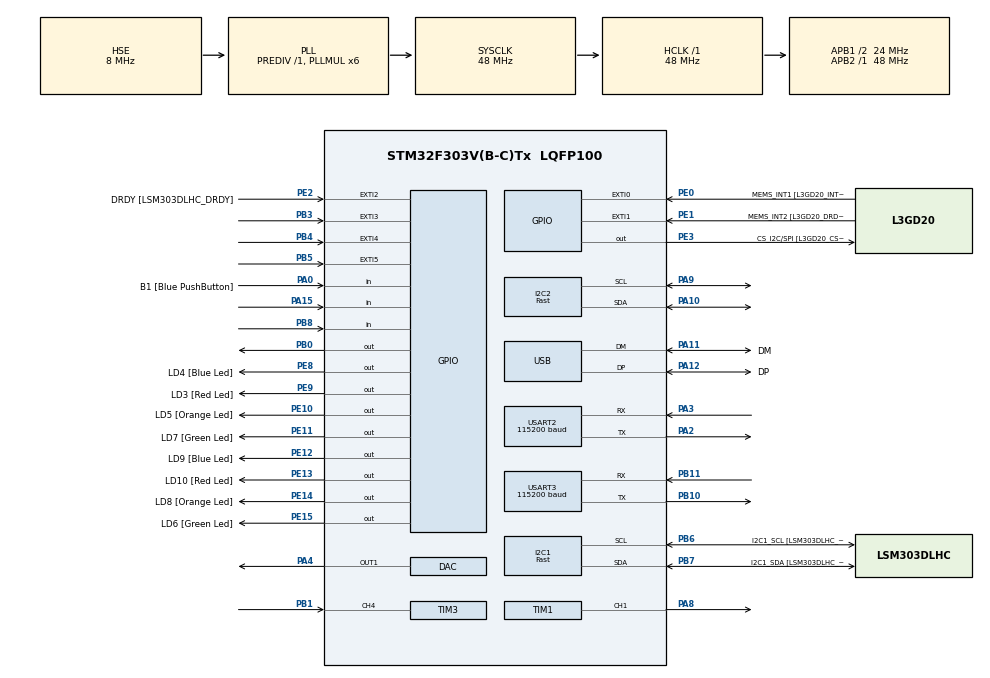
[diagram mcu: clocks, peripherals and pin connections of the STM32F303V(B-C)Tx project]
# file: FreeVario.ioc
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ADC1.Channel-4\#ChannelRegularConversion=ADC_CHANNEL_VBAT
ADC1.ClockPrescaler=ADC_CLOCK_ASYNC_DIV1
ADC1.ContinuousConvMode=ENABLE
ADC1.DMAContinuousRequests=DISABLE
ADC1.DataAlign=ADC_DATAALIGN_RIGHT
ADC1.DiscontinuousConvMode=DISABLE
ADC1.EOCSelection=ADC_EOC_SINGLE_CONV
ADC1.EnableAnalogWatchDog1=false
ADC1.EnableAnalogWatchDog2=false
ADC1.EnableAnalogWatchDog3=false
ADC1.EnableInjectedConversion=ENABLE
ADC1.EnableRegularConversion=ENABLE
ADC1.ExternalTrigConv=ADC_SOFTWARE_START
ADC1.ExternalTrigConvEdge=ADC_EXTERNALTRIGCONVEDGE_NONE
ADC1.InjNumberOfConversion=0
ADC1.LowPowerAutoWait=DISABLE
ADC1.NbrOfConversion=1
ADC1.NbrOfConversionFlag=1
ADC1.Offset-4\#ChannelRegularConversion=0
ADC1.OffsetNumber-4\#ChannelRegularConversion=ADC_OFFSET_NONE
ADC1.Overrun=ADC_OVR_DATA_OVERWRITTEN
ADC1.Rank-4\#ChannelRegularConversion=1
ADC1.Resolution=ADC_RESOLUTION_12B
ADC1.SamplingTime-4\#ChannelRegularConversion=ADC_SAMPLETIME_1CYCLE_5
ADC1.ScanConvMode=ADC_SCAN_DISABLE
ADC1.master=1
DAC.DAC_Trigger=DAC_TRIGGER_T6_TRGO
Dma.DAC_CH1.1.Direction=DMA_MEMORY_TO_PERIPH
Dma.DAC_CH1.1.Instance=DMA1_Channel3
Dma.DAC_CH1.1.MemDataAlignment=DMA_MDATAALIGN_HALFWORD
Dma.DAC_CH1.1.MemInc=DMA_MINC_ENABLE
Dma.DAC_CH1.1.Mode=DMA_CIRCULAR
Dma.DAC_CH1.1.PeriphDataAlignment=DMA_PDATAALIGN_HALFWORD
Dma.DAC_CH1.1.PeriphInc=DMA_PINC_DISABLE
Dma.DAC_CH1.1.Priority=DMA_PRIORITY_LOW
Dma.Request0=USART2_RX
Dma.Request1=DAC_CH1
Dma.USART2_RX.0.Direction=DMA_PERIPH_TO_MEMORY
Dma.USART2_RX.0.Instance=DMA1_Channel6
Dma.USART2_RX.0.MemDataAlignment=DMA_MDATAALIGN_BYTE
Dma.USART2_RX.0.MemInc=DMA_MINC_ENABLE
Dma.USART2_RX.0.Mode=DMA_CIRCULAR
Dma.USART2_RX.0.PeriphDataAlignment=DMA_PDATAALIGN_BYTE
Dma.USART2_RX.0.PeriphInc=DMA_PINC_DISABLE
Dma.USART2_RX.0.Priority=DMA_PRIORITY_LOW
I2C1.Analog_Filter=I2C_ANALOGFILTER_ENABLE
I2C1.I2C_Coeff_DF=0
I2C1.I2C_Speed_Mode=I2C_Fast
I2C1.Timing=0x2010091A
I2C2.I2C_Coeff_DF=2
I2C2.I2C_Speed_Mode=I2C_Fast
I2C2.Timing=0x00401653
IWDG.Prescaler=IWDG_PRESCALER_32
Mcu.Family=STM32F3
Mcu.Name=STM32F303V(B-C)Tx
Mcu.Package=LQFP100
NVIC.DMA1_Channel3_IRQn=true\:0\:0\:false\:false\:true\:false
NVIC.DMA1_Channel6_IRQn=true\:0\:0\:false\:false\:true\:false
NVIC.EXTI3_IRQn=true\:0\:0\:false\:false\:true\:true
NVIC.EXTI4_IRQn=true\:0\:0\:false\:false\:true\:true
NVIC.EXTI9_5_IRQn=true\:0\:0\:false\:false\:true\:true
NVIC.PriorityGroup=NVIC_PRIORITYGROUP_0
NVIC.USB_LP_CAN_RX0_IRQn=true\:0\:0\:false\:false\:true\:false
PA0.GPIO_Label=B1 [Blue PushButton]
PA0.GPIO_Mode=GPIO_MODE_INPUT
PA0.GPIO_PuPd=GPIO_NOPULL
PA0.Signal=GPIO_Input
PA10.Mode=I2C
PA10.Signal=I2C2_SDA
PA11.GPIO_Label=DM
PA11.Mode=Device
PA11.Signal=USB_DM
PA12.GPIO_Label=DP
PA12.Mode=Device
PA12.Signal=USB_DP
PA13.GPIO_Label=SWDIO
PA13.Mode=Serial_Wire
PA13.Signal=SYS_JTMS-SWDIO
PA14.GPIO_Label=SWCLK
PA14.Mode=Serial_Wire
PA14.Signal=SYS_JTCK-SWCLK
PA15.Signal=GPIO_Input
PA2.Mode=Asynchronous
PA2.Signal=USART2_TX
PA3.Mode=Asynchronous
PA3.Signal=USART2_RX
PA4.Signal=COMP_DAC1_group
PA5.GPIO_Label=SPI1_SCK [L3GD20_SCL/SPC]
PA5.GPIO_Mode=GPIO_MODE_AF_PP
PA5.GPIO_PuPd=GPIO_NOPULL
PA5.GPIO_Speed=GPIO_SPEED_FREQ_LOW
PA5.Signal=SPI1_SCK
PA6.GPIO_Label=SPI1_MISO [L3GD20_SA0/SDO]
PA6.GPIO_Mode=GPIO_MODE_AF_PP
PA6.GPIO_PuPd=GPIO_NOPULL
PA6.GPIO_Speed=GPIO_SPEED_FREQ_LOW
PA6.Signal=SPI1_MISO
PA7.GPIO_Label=SPI1_MISO [L3GD20_SDA/SDI/SDO]
PA7.GPIO_Mode=GPIO_MODE_AF_PP
PA7.GPIO_PuPd=GPIO_NOPULL
PA7.GPIO_Speed=GPIO_SPEED_FREQ_LOW
PA7.Signal=SPI1_MOSI
PA8.Signal=S_TIM1_CH1
PA9.Mode=I2C
PA9.Signal=I2C2_SCL
PB0.Signal=GPIO_Output
PB1.Signal=S_TIM3_CH4
PB10.Mode=Asynchronous
PB10.Signal=USART3_TX
PB11.Mode=Asynchronous
PB11.Signal=USART3_RX
PB3.Signal=GPXTI3
PB4.Signal=GPXTI4
PB5.Signal=GPXTI5
PB6.GPIO_FM6=__NULL
PB6.GPIO_Label=I2C1_SCL [LSM303DLHC_SCL]
PB6.GPIO_Mode=GPIO_MODE_AF_OD
PB6.GPIO_PuPd=GPIO_NOPULL
PB6.GPIO_Speed=GPIO_SPEED_FREQ_LOW
PB6.Mode=I2C
PB6.Signal=I2C1_SCL
PB7.GPIO_FM7=__NULL
PB7.GPIO_Label=I2C1_SDA [LSM303DLHC_SDA]
PB7.GPIO_Mode=GPIO_MODE_AF_OD
PB7.GPIO_PuPd=GPIO_NOPULL
PB7.GPIO_Speed=GPIO_SPEED_FREQ_LOW
PB7.Mode=I2C
PB7.Signal=I2C1_SDA
PB8.Signal=GPIO_Input
PC14-OSC32_IN.GPIO_Label=OSC32_IN
PC14-OSC32_IN.Signal=RCC_OSC32_IN
PC15-OSC32_OUT.GPIO_Label=OSC32_OUT
PC15-OSC32_OUT.Signal=RCC_OSC32_OUT
PE0.GPIO_Label=MEMS_INT1 [L3GD20_INT1]
PE0.GPIO_ModeDefaultEXTI=GPIO_MODE_EVT_RISING
PE0.GPIO_PuPd=GPIO_NOPULL
PE0.Signal=GPXTI0
PE1.GPIO_Label=MEMS_INT2 [L3GD20_DRDY/INT2]
PE1.GPIO_ModeDefaultEXTI=GPIO_MODE_EVT_RISING
PE1.GPIO_PuPd=GPIO_NOPULL
PE1.Signal=GPXTI1
PE10.GPIO_Label=LD5 [Orange Led]
PE10.GPIO_ModeDefaultOutputPP=GPIO_MODE_OUTPUT_PP
PE10.GPIO_PuPd=GPIO_NOPULL
PE10.GPIO_Speed=GPIO_SPEED_FREQ_LOW
PE10.Signal=GPIO_Output
PE11.GPIO_Label=LD7 [Green Led]
PE11.GPIO_ModeDefaultOutputPP=GPIO_MODE_OUTPUT_PP
PE11.GPIO_PuPd=GPIO_NOPULL
PE11.GPIO_Speed=GPIO_SPEED_FREQ_LOW
PE11.Signal=GPIO_Output
PE12.GPIO_Label=LD9 [Blue Led]
PE12.GPIO_ModeDefaultOutputPP=GPIO_MODE_OUTPUT_PP
PE12.GPIO_PuPd=GPIO_NOPULL
PE12.GPIO_Speed=GPIO_SPEED_FREQ_LOW
PE12.Signal=GPIO_Output
PE13.GPIO_Label=LD10 [Red Led]
PE13.GPIO_ModeDefaultOutputPP=GPIO_MODE_OUTPUT_PP
PE13.GPIO_PuPd=GPIO_NOPULL
PE13.GPIO_Speed=GPIO_SPEED_FREQ_LOW
PE13.Signal=GPIO_Output
PE14.GPIO_Label=LD8 [Orange Led]
PE14.GPIO_ModeDefaultOutputPP=GPIO_MODE_OUTPUT_PP
PE14.GPIO_PuPd=GPIO_NOPULL
PE14.GPIO_Speed=GPIO_SPEED_FREQ_LOW
PE14.Signal=GPIO_Output
PE15.GPIO_Label=LD6 [Green Led]
PE15.GPIO_ModeDefaultOutputPP=GPIO_MODE_OUTPUT_PP
PE15.GPIO_PuPd=GPIO_NOPULL
PE15.GPIO_Speed=GPIO_SPEED_FREQ_LOW
PE15.Signal=GPIO_Output
PE2.GPIO_Label=DRDY [LSM303DLHC_DRDY]
PE2.GPIO_ModeDefaultEXTI=GPIO_MODE_EVT_RISING
PE2.GPIO_PuPd=GPIO_NOPULL
PE2.Signal=GPXTI2
PE3.GPIO_Label=CS_I2C/SPI [L3GD20_CS_I2C/SPI]
PE3.GPIO_ModeDefaultOutputPP=GPIO_MODE_OUTPUT_PP
PE3.GPIO_PuPd=GPIO_NOPULL
PE3.GPIO_Speed=GPIO_SPEED_FREQ_LOW
PE3.Signal=GPIO_Output
PE8.GPIO_Label=LD4 [Blue Led]
PE8.GPIO_ModeDefaultOutputPP=GPIO_MODE_OUTPUT_PP
PE8.GPIO_PuPd=GPIO_NOPULL
PE8.GPIO_Speed=GPIO_SPEED_FREQ_LOW
PE8.Signal=GPIO_Output
PE9.GPIO_Label=LD3 [Red Led]
PE9.GPIO_ModeDefaultOutputPP=GPIO_MODE_OUTPUT_PP
PE9.GPIO_PuPd=GPIO_NOPULL
PE9.GPIO_Speed=GPIO_SPEED_FREQ_LOW
PE9.Signal=GPIO_Output
PF0-OSC_IN.GPIO_Label=OSC_IN
PF0-OSC_IN.Mode=HSE-External-Clock-Source
PF0-OSC_IN.Signal=RCC_OSC_IN
PF1-OSC_OUT.GPIO_Label=OSC_OUT
PF1-OSC_OUT.Signal=RCC_OSC_OUT
ProjectManager.HeapSize=0x200
ProjectManager.StackSize=0x400
ProjectManager.TargetToolchain=TrueSTUDIO
RCC.AHBFreq_Value=48000000
RCC.APB1CLKDivider=RCC_HCLK_DIV2
RCC.APB1Freq_Value=24000000
RCC.APB1TimFreq_Value=48000000
RCC.APB2Freq_Value=48000000
RCC.APB2TimFreq_Value=48000000
RCC.CortexFreq_Value=48000000
RCC.HCLKFreq_Value=48000000
RCC.HSE_VALUE=8000000
RCC.HSI_VALUE=8000000
RCC.I2c1ClockSelection=RCC_I2C1CLKSOURCE_SYSCLK
RCC.I2c2ClockSelection=RCC_I2C2CLKSOURCE_SYSCLK
RCC.LSE_VALUE=32768
RCC.PLLMUL=RCC_PLL_MUL6
RCC.SYSCLKFreq_VALUE=48000000
RCC.SYSCLKSourceVirtual=RCC_SYSCLKSOURCE_PLLCLK
RCC.USBFreq_Value=48000000
SH.COMP_DAC1_group.0=DAC_OUT1,DAC_OUT1
SH.S_TIM1_CH1.0=TIM1_CH1,PWM Generation1 CH1
SH.S_TIM3_CH4.0=TIM3_CH4,Input_Capture4_from_TI4
TIM1.Channel-PWM\ Generation1\ CH1=TIM_CHANNEL_1
TIM1.OCPolarity_1=TIM_OCPOLARITY_LOW
TIM3.Channel-Input_Capture4_from_TI4=TIM_CHANNEL_4
TIM6.TIM_MasterOutputTrigger=TIM_TRGO_UPDATE
USART2.BaudRate=115200
USART2.DMADisableonRxErrorParam=ADVFEATURE_DMA_DISABLEONRXERROR
USART2.OverSampling=UART_OVERSAMPLING_8
USART2.OverrunDisableParam=ADVFEATURE_OVERRUN_DISABLE
USART2.VirtualMode-Asynchronous=VM_ASYNC
USART3.BaudRate=115200
USART3.VirtualMode-Asynchronous=VM_ASYNC
USB_DEVICE.CLASS_NAME_FS=CDC
USB_DEVICE.VirtualMode=Cdc
USB_DEVICE.VirtualModeFS=Cdc_FS
VP_ADC1_Vbat_Input.Mode=IN-Vbat
VP_IWDG_VS_IWDG.Mode=IWDG_Activate
VP_TIM1_VS_ClockSourceINT.Mode=Internal
VP_TIM6_VS_ClockSourceINT.Mode=Enable_Timer
VP_USB_DEVICE_VS_USB_DEVICE_CDC_FS.Mode=CDC_FS
board=STM32F3DISCOVERY

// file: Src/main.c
/**
  ******************************************************************************
  * File Name          : main.c
  * Description        : Main program body
  ******************************************************************************
  * This notice applies to any and all portions of this file
  * that are not between comment pairs USER CODE BEGIN and
  * USER CODE END. Other portions of this file, whether
  * inserted by the user or by software development tools
  * are owned by their respective copyright owners.
  *
  * Copyright (c) 2018 STMicroelectronics International N.V.
  * All rights reserved.
  *
  * Redistribution and use in source and binary forms, with or without
  * modification, are permitted, provided that the following conditions are met:
  *
  * 1. Redistribution of source code must retain the above copyright notice,
  *    this list of conditions and the following disclaimer.
  * 2. Redistributions in binary form must reproduce the above copyright notice,
  *    this list of conditions and the following disclaimer in the documentation
  *    and/or other materials provided with the distribution.
  * 3. Neither the name of STMicroelectronics nor the names of other
  *    contributors to this software may be used to endorse or promote products
  *    derived from this software without specific written permission.
  * 4. This software, including modifications and/or derivative works of this
  *    software, must execute solely and exclusively on microcontroller or
  *    microprocessor devices manufactured by or for STMicroelectronics.
  * 5. Redistribution and use of this software other than as permitted under
  *    this license is void and will automatically terminate your rights under
  *    this license.
  *
  * THIS SOFTWARE IS PROVIDED BY STMICROELECTRONICS AND CONTRIBUTORS "AS IS"
  * AND ANY EXPRESS, IMPLIED OR STATUTORY WARRANTIES, INCLUDING, BUT NOT
  * LIMITED TO, THE IMPLIED WARRANTIES OF MERCHANTABILITY, FITNESS FOR A
  * PARTICULAR PURPOSE AND NON-INFRINGEMENT OF THIRD PARTY INTELLECTUAL PROPERTY
  * RIGHTS ARE DISCLAIMED TO THE FULLEST EXTENT PERMITTED BY LAW. IN NO EVENT
  * SHALL STMICROELECTRONICS OR CONTRIBUTORS BE LIABLE FOR ANY DIRECT, INDIRECT,
  * INCIDENTAL, SPECIAL, EXEMPLARY, OR CONSEQUENTIAL DAMAGES (INCLUDING, BUT NOT
  * LIMITED TO, PROCUREMENT OF SUBSTITUTE GOODS OR SERVICES; LOSS OF USE, DATA,
  * OR PROFITS; OR BUSINESS INTERRUPTION) HOWEVER CAUSED AND ON ANY THEORY OF
  * LIABILITY, WHETHER IN CONTRACT, STRICT LIABILITY, OR TORT (INCLUDING
  * NEGLIGENCE OR OTHERWISE) ARISING IN ANY WAY OUT OF THE USE OF THIS SOFTWARE,
  * EVEN IF ADVISED OF THE POSSIBILITY OF SUCH DAMAGE.
  *
  ******************************************************************************
  */

#include "main.h"
#include "stm32f3xx_hal.h"
#include "usb_device.h"

/* USER CODE BEGIN Includes */
#include "freevario.h"
/* USER CODE END Includes */

ADC_HandleTypeDef hadc1;

DAC_HandleTypeDef hdac;
DMA_HandleTypeDef hdma_dac_ch1;

I2C_HandleTypeDef hi2c1;
I2C_HandleTypeDef hi2c2;

IWDG_HandleTypeDef hiwdg;

TIM_HandleTypeDef htim1;
TIM_HandleTypeDef htim3;
TIM_HandleTypeDef htim6;

UART_HandleTypeDef huart2;
UART_HandleTypeDef huart3;
DMA_HandleTypeDef hdma_usart2_rx;

/* USER CODE BEGIN PV */
/* Private variables ---------------------------------------------------------*/

/* USER CODE END PV */

void SystemClock_Config(void);
static void MX_GPIO_Init(void);
static void MX_DMA_Init(void);
static void MX_I2C1_Init(void);
static void MX_I2C2_Init(void);
static void MX_USART2_UART_Init(void);
static void MX_TIM1_Init(void);
static void MX_TIM3_Init(void);
static void MX_USART3_UART_Init(void);
static void MX_DAC_Init(void);
static void MX_TIM6_Init(void);
static void MX_IWDG_Init(void);
static void MX_ADC1_Init(void);

void HAL_TIM_MspPostInit(TIM_HandleTypeDef *htim);

/* USER CODE BEGIN PFP */
/* Private function prototypes -----------------------------------------------*/

/* USER CODE END PFP */

int main(void)
{

  /* MCU Configuration----------------------------------------------------------*/

  /* Reset of all peripherals, Initializes the Flash interface and the Systick. */
  HAL_Init();

  /* Configure the system clock */
  SystemClock_Config();

  /* Initialize all configured peripherals */
  MX_GPIO_Init();
  MX_DMA_Init();
  MX_I2C1_Init();
  MX_I2C2_Init();
  MX_USB_DEVICE_Init();
  MX_USART2_UART_Init();
  MX_TIM1_Init();
  MX_TIM3_Init();
  MX_USART3_UART_Init();
  MX_DAC_Init();
  MX_TIM6_Init();
  MX_IWDG_Init();
  MX_ADC1_Init();

  /* USER CODE BEGIN 2 */

  FV_Run();
  /* USER CODE END 2 */

  /* Infinite loop */
  while (1)
  {

  }

}

/** System Clock Configuration
*/
void SystemClock_Config(void)
{

  RCC_OscInitTypeDef RCC_OscInitStruct;
  RCC_ClkInitTypeDef RCC_ClkInitStruct;
  RCC_PeriphCLKInitTypeDef PeriphClkInit;

    /**Initializes the CPU, AHB and APB busses clocks
    */
  RCC_OscInitStruct.OscillatorType = RCC_OSCILLATORTYPE_LSI|RCC_OSCILLATORTYPE_HSE;
  RCC_OscInitStruct.HSEState = RCC_HSE_BYPASS;
  RCC_OscInitStruct.HSEPredivValue = RCC_HSE_PREDIV_DIV1;
  RCC_OscInitStruct.HSIState = RCC_HSI_ON;
  RCC_OscInitStruct.LSIState = RCC_LSI_ON;
  RCC_OscInitStruct.PLL.PLLState = RCC_PLL_ON;
  RCC_OscInitStruct.PLL.PLLSource = RCC_PLLSOURCE_HSE;
  RCC_OscInitStruct.PLL.PLLMUL = RCC_PLL_MUL6;
  if (HAL_RCC_OscConfig(&RCC_OscInitStruct) != HAL_OK)
  {
    _Error_Handler(__FILE__, __LINE__);
  }

    /**Initializes the CPU, AHB and APB busses clocks
    */
  RCC_ClkInitStruct.ClockType = RCC_CLOCKTYPE_HCLK|RCC_CLOCKTYPE_SYSCLK
                              |RCC_CLOCKTYPE_PCLK1|RCC_CLOCKTYPE_PCLK2;
  RCC_ClkInitStruct.SYSCLKSource = RCC_SYSCLKSOURCE_PLLCLK;
  RCC_ClkInitStruct.AHBCLKDivider = RCC_SYSCLK_DIV1;
  RCC_ClkInitStruct.APB1CLKDivider = RCC_HCLK_DIV2;
  RCC_ClkInitStruct.APB2CLKDivider = RCC_HCLK_DIV1;

  if (HAL_RCC_ClockConfig(&RCC_ClkInitStruct, FLASH_LATENCY_1) != HAL_OK)
  {
    _Error_Handler(__FILE__, __LINE__);
  }

  PeriphClkInit.PeriphClockSelection = RCC_PERIPHCLK_USB|RCC_PERIPHCLK_USART2
                              |RCC_PERIPHCLK_USART3|RCC_PERIPHCLK_I2C1
                              |RCC_PERIPHCLK_I2C2|RCC_PERIPHCLK_TIM1
                              |RCC_PERIPHCLK_ADC12;
  PeriphClkInit.Usart2ClockSelection = RCC_USART2CLKSOURCE_PCLK1;
  PeriphClkInit.Usart3ClockSelection = RCC_USART3CLKSOURCE_PCLK1;
  PeriphClkInit.Adc12ClockSelection = RCC_ADC12PLLCLK_DIV1;
  PeriphClkInit.I2c1ClockSelection = RCC_I2C1CLKSOURCE_SYSCLK;
  PeriphClkInit.I2c2ClockSelection = RCC_I2C2CLKSOURCE_SYSCLK;
  PeriphClkInit.USBClockSelection = RCC_USBCLKSOURCE_PLL;
  PeriphClkInit.Tim1ClockSelection = RCC_TIM1CLK_HCLK;
  if (HAL_RCCEx_PeriphCLKConfig(&PeriphClkInit) != HAL_OK)
  {
    _Error_Handler(__FILE__, __LINE__);
  }

    /**Configure the Systick interrupt time
    */
  HAL_SYSTICK_Config(HAL_RCC_GetHCLKFreq()/1000);

    /**Configure the Systick
    */
  HAL_SYSTICK_CLKSourceConfig(SYSTICK_CLKSOURCE_HCLK);

  /* SysTick_IRQn interrupt configuration */
  HAL_NVIC_SetPriority(SysTick_IRQn, 0, 0);
}

/* ADC1 init function */
static void MX_ADC1_Init(void)
{

  ADC_MultiModeTypeDef multimode;
  ADC_ChannelConfTypeDef sConfig;

    /**Common config
    */
  hadc1.Instance = ADC1;
  hadc1.Init.ClockPrescaler = ADC_CLOCK_ASYNC_DIV1;
  hadc1.Init.Resolution = ADC_RESOLUTION_12B;
  hadc1.Init.ScanConvMode = ADC_SCAN_DISABLE;
  hadc1.Init.ContinuousConvMode = ENABLE;
  hadc1.Init.DiscontinuousConvMode = DISABLE;
  hadc1.Init.ExternalTrigConvEdge = ADC_EXTERNALTRIGCONVEDGE_NONE;
  hadc1.Init.ExternalTrigConv = ADC_SOFTWARE_START;
  hadc1.Init.DataAlign = ADC_DATAALIGN_RIGHT;
  hadc1.Init.NbrOfConversion = 1;
  hadc1.Init.DMAContinuousRequests = DISABLE;
  hadc1.Init.EOCSelection = ADC_EOC_SINGLE_CONV;
  hadc1.Init.LowPowerAutoWait = DISABLE;
  hadc1.Init.Overrun = ADC_OVR_DATA_OVERWRITTEN;
  if (HAL_ADC_Init(&hadc1) != HAL_OK)
  {
    _Error_Handler(__FILE__, __LINE__);
  }

    /**Configure the ADC multi-mode
    */
  multimode.Mode = ADC_MODE_INDEPENDENT;
  if (HAL_ADCEx_MultiModeConfigChannel(&hadc1, &multimode) != HAL_OK)
  {
    _Error_Handler(__FILE__, __LINE__);
  }

    /**Configure Regular Channel
    */
  sConfig.Channel = ADC_CHANNEL_VBAT;
  sConfig.Rank = 1;
  sConfig.SingleDiff = ADC_SINGLE_ENDED;
  sConfig.SamplingTime = ADC_SAMPLETIME_1CYCLE_5;
  sConfig.OffsetNumber = ADC_OFFSET_NONE;
  sConfig.Offset = 0;
  if (HAL_ADC_ConfigChannel(&hadc1, &sConfig) != HAL_OK)
  {
    _Error_Handler(__FILE__, __LINE__);
  }

}

/* DAC init function */
static void MX_DAC_Init(void)
{

  DAC_ChannelConfTypeDef sConfig;

    /**DAC Initialization
    */
  hdac.Instance = DAC;
  if (HAL_DAC_Init(&hdac) != HAL_OK)
  {
    _Error_Handler(__FILE__, __LINE__);
  }

    /**DAC channel OUT1 config
    */
  sConfig.DAC_Trigger = DAC_TRIGGER_T6_TRGO;
  sConfig.DAC_OutputBuffer = DAC_OUTPUTBUFFER_ENABLE;
  if (HAL_DAC_ConfigChannel(&hdac, &sConfig, DAC_CHANNEL_1) != HAL_OK)
  {
    _Error_Handler(__FILE__, __LINE__);
  }

}

/* I2C1 init function */
static void MX_I2C1_Init(void)
{

  hi2c1.Instance = I2C1;
  hi2c1.Init.Timing = 0x2010091A;
  hi2c1.Init.OwnAddress1 = 0;
  hi2c1.Init.AddressingMode = I2C_ADDRESSINGMODE_7BIT;
  hi2c1.Init.DualAddressMode = I2C_DUALADDRESS_DISABLE;
  hi2c1.Init.OwnAddress2 = 0;
  hi2c1.Init.OwnAddress2Masks = I2C_OA2_NOMASK;
  hi2c1.Init.GeneralCallMode = I2C_GENERALCALL_DISABLE;
  hi2c1.Init.NoStretchMode = I2C_NOSTRETCH_DISABLE;
  if (HAL_I2C_Init(&hi2c1) != HAL_OK)
  {
    _Error_Handler(__FILE__, __LINE__);
  }

    /**Configure Analogue filter
    */
  if (HAL_I2CEx_ConfigAnalogFilter(&hi2c1, I2C_ANALOGFILTER_ENABLE) != HAL_OK)
  {
    _Error_Handler(__FILE__, __LINE__);
  }

    /**Configure Digital filter
    */
  if (HAL_I2CEx_ConfigDigitalFilter(&hi2c1, 0) != HAL_OK)
  {
    _Error_Handler(__FILE__, __LINE__);
  }

}

/* I2C2 init function */
static void MX_I2C2_Init(void)
{

  hi2c2.Instance = I2C2;
  hi2c2.Init.Timing = 0x00401653;
  hi2c2.Init.OwnAddress1 = 0;
  hi2c2.Init.AddressingMode = I2C_ADDRESSINGMODE_7BIT;
  hi2c2.Init.DualAddressMode = I2C_DUALADDRESS_DISABLE;
  hi2c2.Init.OwnAddress2 = 0;
  hi2c2.Init.OwnAddress2Masks = I2C_OA2_NOMASK;
  hi2c2.Init.GeneralCallMode = I2C_GENERALCALL_DISABLE;
  hi2c2.Init.NoStretchMode = I2C_NOSTRETCH_DISABLE;
  if (HAL_I2C_Init(&hi2c2) != HAL_OK)
  {
    _Error_Handler(__FILE__, __LINE__);
  }

    /**Configure Analogue filter
    */
  if (HAL_I2CEx_ConfigAnalogFilter(&hi2c2, I2C_ANALOGFILTER_ENABLE) != HAL_OK)
  {
    _Error_Handler(__FILE__, __LINE__);
  }

    /**Configure Digital filter
    */
  if (HAL_I2CEx_ConfigDigitalFilter(&hi2c2, 2) != HAL_OK)
  {
    _Error_Handler(__FILE__, __LINE__);
  }

}

/* IWDG init function */
static void MX_IWDG_Init(void)
{

  hiwdg.Instance = IWDG;
  hiwdg.Init.Prescaler = IWDG_PRESCALER_32;
  hiwdg.Init.Window = 4095;
  hiwdg.Init.Reload = 4095;
  if (HAL_IWDG_Init(&hiwdg) != HAL_OK)
  {
    _Error_Handler(__FILE__, __LINE__);
  }

}

/* TIM1 init function */
static void MX_TIM1_Init(void)
{

  TIM_ClockConfigTypeDef sClockSourceConfig;
  TIM_MasterConfigTypeDef sMasterConfig;
  TIM_OC_InitTypeDef sConfigOC;
  TIM_BreakDeadTimeConfigTypeDef sBreakDeadTimeConfig;

  htim1.Instance = TIM1;
  htim1.Init.Prescaler = 0;
  htim1.Init.CounterMode = TIM_COUNTERMODE_UP;
  htim1.Init.Period = 0;
  htim1.Init.ClockDivision = TIM_CLOCKDIVISION_DIV1;
  htim1.Init.RepetitionCounter = 0;
  htim1.Init.AutoReloadPreload = TIM_AUTORELOAD_PRELOAD_DISABLE;
  if (HAL_TIM_Base_Init(&htim1) != HAL_OK)
  {
    _Error_Handler(__FILE__, __LINE__);
  }

  sClockSourceConfig.ClockSource = TIM_CLOCKSOURCE_INTERNAL;
  if (HAL_TIM_ConfigClockSource(&htim1, &sClockSourceConfig) != HAL_OK)
  {
    _Error_Handler(__FILE__, __LINE__);
  }

  if (HAL_TIM_PWM_Init(&htim1) != HAL_OK)
  {
    _Error_Handler(__FILE__, __LINE__);
  }

  sMasterConfig.MasterOutputTrigger = TIM_TRGO_RESET;
  sMasterConfig.MasterOutputTrigger2 = TIM_TRGO2_RESET;
  sMasterConfig.MasterSlaveMode = TIM_MASTERSLAVEMODE_DISABLE;
  if (HAL_TIMEx_MasterConfigSynchronization(&htim1, &sMasterConfig) != HAL_OK)
  {
    _Error_Handler(__FILE__, __LINE__);
  }

  sConfigOC.OCMode = TIM_OCMODE_PWM1;
  sConfigOC.Pulse = 0;
  sConfigOC.OCPolarity = TIM_OCPOLARITY_LOW;
  sConfigOC.OCNPolarity = TIM_OCNPOLARITY_HIGH;
  sConfigOC.OCFastMode = TIM_OCFAST_DISABLE;
  sConfigOC.OCIdleState = TIM_OCIDLESTATE_RESET;
  sConfigOC.OCNIdleState = TIM_OCNIDLESTATE_RESET;
  if (HAL_TIM_PWM_ConfigChannel(&htim1, &sConfigOC, TIM_CHANNEL_1) != HAL_OK)
  {
    _Error_Handler(__FILE__, __LINE__);
  }

  sBreakDeadTimeConfig.OffStateRunMode = TIM_OSSR_DISABLE;
  sBreakDeadTimeConfig.OffStateIDLEMode = TIM_OSSI_DISABLE;
  sBreakDeadTimeConfig.LockLevel = TIM_LOCKLEVEL_OFF;
  sBreakDeadTimeConfig.DeadTime = 0;
  sBreakDeadTimeConfig.BreakState = TIM_BREAK_DISABLE;
  sBreakDeadTimeConfig.BreakPolarity = TIM_BREAKPOLARITY_HIGH;
  sBreakDeadTimeConfig.BreakFilter = 0;
  sBreakDeadTimeConfig.Break2State = TIM_BREAK2_DISABLE;
  sBreakDeadTimeConfig.Break2Polarity = TIM_BREAK2POLARITY_HIGH;
  sBreakDeadTimeConfig.Break2Filter = 0;
  sBreakDeadTimeConfig.AutomaticOutput = TIM_AUTOMATICOUTPUT_DISABLE;
  if (HAL_TIMEx_ConfigBreakDeadTime(&htim1, &sBreakDeadTimeConfig) != HAL_OK)
  {
    _Error_Handler(__FILE__, __LINE__);
  }

  HAL_TIM_MspPostInit(&htim1);

}

/* TIM3 init function */
static void MX_TIM3_Init(void)
{

  TIM_MasterConfigTypeDef sMasterConfig;
  TIM_IC_InitTypeDef sConfigIC;

  htim3.Instance = TIM3;
  htim3.Init.Prescaler = 0;
  htim3.Init.CounterMode = TIM_COUNTERMODE_UP;
  htim3.Init.Period = 0;
  htim3.Init.ClockDivision = TIM_CLOCKDIVISION_DIV1;
  htim3.Init.AutoReloadPreload = TIM_AUTORELOAD_PRELOAD_DISABLE;
  if (HAL_TIM_IC_Init(&htim3) != HAL_OK)
  {
    _Error_Handler(__FILE__, __LINE__);
  }

  sMasterConfig.MasterOutputTrigger = TIM_TRGO_RESET;
  sMasterConfig.MasterSlaveMode = TIM_MASTERSLAVEMODE_DISABLE;
  if (HAL_TIMEx_MasterConfigSynchronization(&htim3, &sMasterConfig) != HAL_OK)
  {
    _Error_Handler(__FILE__, __LINE__);
  }

  sConfigIC.ICPolarity = TIM_INPUTCHANNELPOLARITY_RISING;
  sConfigIC.ICSelection = TIM_ICSELECTION_DIRECTTI;
  sConfigIC.ICPrescaler = TIM_ICPSC_DIV1;
  sConfigIC.ICFilter = 0;
  if (HAL_TIM_IC_ConfigChannel(&htim3, &sConfigIC, TIM_CHANNEL_4) != HAL_OK)
  {
    _Error_Handler(__FILE__, __LINE__);
  }

}

/* TIM6 init function */
static void MX_TIM6_Init(void)
{

  TIM_MasterConfigTypeDef sMasterConfig;

  htim6.Instance = TIM6;
  htim6.Init.Prescaler = 0;
  htim6.Init.CounterMode = TIM_COUNTERMODE_UP;
  htim6.Init.Period = 0;
  htim6.Init.AutoReloadPreload = TIM_AUTORELOAD_PRELOAD_DISABLE;
  if (HAL_TIM_Base_Init(&htim6) != HAL_OK)
  {
    _Error_Handler(__FILE__, __LINE__);
  }

  sMasterConfig.MasterOutputTrigger = TIM_TRGO_UPDATE;
  sMasterConfig.MasterSlaveMode = TIM_MASTERSLAVEMODE_DISABLE;
  if (HAL_TIMEx_MasterConfigSynchronization(&htim6, &sMasterConfig) != HAL_OK)
  {
    _Error_Handler(__FILE__, __LINE__);
  }

}

/* USART2 init function */
static void MX_USART2_UART_Init(void)
{

  huart2.Instance = USART2;
  huart2.Init.BaudRate = 115200;
  huart2.Init.WordLength = UART_WORDLENGTH_8B;
  huart2.Init.StopBits = UART_STOPBITS_1;
  huart2.Init.Parity = UART_PARITY_NONE;
  huart2.Init.Mode = UART_MODE_TX_RX;
  huart2.Init.HwFlowCtl = UART_HWCONTROL_NONE;
  huart2.Init.OverSampling = UART_OVERSAMPLING_8;
  huart2.Init.OneBitSampling = UART_ONE_BIT_SAMPLE_DISABLE;
  huart2.AdvancedInit.AdvFeatureInit = UART_ADVFEATURE_RXOVERRUNDISABLE_INIT|UART_ADVFEATURE_DMADISABLEONERROR_INIT;
  huart2.AdvancedInit.OverrunDisable = UART_ADVFEATURE_OVERRUN_DISABLE;
  huart2.AdvancedInit.DMADisableonRxError = UART_ADVFEATURE_DMA_DISABLEONRXERROR;
  if (HAL_UART_Init(&huart2) != HAL_OK)
  {
    _Error_Handler(__FILE__, __LINE__);
  }

}

/* USART3 init function */
static void MX_USART3_UART_Init(void)
{

  huart3.Instance = USART3;
  huart3.Init.BaudRate = 115200;
  huart3.Init.WordLength = UART_WORDLENGTH_8B;
  huart3.Init.StopBits = UART_STOPBITS_1;
  huart3.Init.Parity = UART_PARITY_NONE;
  huart3.Init.Mode = UART_MODE_TX_RX;
  huart3.Init.HwFlowCtl = UART_HWCONTROL_NONE;
  huart3.Init.OverSampling = UART_OVERSAMPLING_16;
  huart3.Init.OneBitSampling = UART_ONE_BIT_SAMPLE_DISABLE;
  huart3.AdvancedInit.AdvFeatureInit = UART_ADVFEATURE_NO_INIT;
  if (HAL_UART_Init(&huart3) != HAL_OK)
  {
    _Error_Handler(__FILE__, __LINE__);
  }

}

static void MX_DMA_Init(void)
{
  /* DMA controller clock enable */
  __HAL_RCC_DMA1_CLK_ENABLE();

  /* DMA interrupt init */
  /* DMA1_Channel3_IRQn interrupt configuration */
  HAL_NVIC_SetPriority(DMA1_Channel3_IRQn, 0, 0);
  HAL_NVIC_EnableIRQ(DMA1_Channel3_IRQn);
  /* DMA1_Channel6_IRQn interrupt configuration */
  HAL_NVIC_SetPriority(DMA1_Channel6_IRQn, 0, 0);
  HAL_NVIC_EnableIRQ(DMA1_Channel6_IRQn);

}

/** Configure pins as
        * Analog
        * Input
        * Output
        * EVENT_OUT
        * EXTI
     PA5   ------> SPI1_SCK
     PA6   ------> SPI1_MISO
     PA7   ------> SPI1_MOSI
*/
static void MX_GPIO_Init(void)
{

  GPIO_InitTypeDef GPIO_InitStruct;

  /* GPIO Ports Clock Enable */
  __HAL_RCC_GPIOE_CLK_ENABLE();
  __HAL_RCC_GPIOC_CLK_ENABLE();
  __HAL_RCC_GPIOF_CLK_ENABLE();
  __HAL_RCC_GPIOA_CLK_ENABLE();
  __HAL_RCC_GPIOB_CLK_ENABLE();

  /*Configure GPIO pin Output Level */
  HAL_GPIO_WritePin(GPIOE, CS_I2C_SPI_Pin|LD4_Pin|LD3_Pin|LD5_Pin
                          |LD7_Pin|LD9_Pin|LD10_Pin|LD8_Pin
                          |LD6_Pin, GPIO_PIN_RESET);

  /*Configure GPIO pin Output Level */
  HAL_GPIO_WritePin(GPIOB, GPIO_PIN_0, GPIO_PIN_RESET);

  /*Configure GPIO pins : DRDY_Pin MEMS_INT1_Pin MEMS_INT2_Pin */
  GPIO_InitStruct.Pin = DRDY_Pin|MEMS_INT1_Pin|MEMS_INT2_Pin;
  GPIO_InitStruct.Mode = GPIO_MODE_EVT_RISING;
  GPIO_InitStruct.Pull = GPIO_NOPULL;
  HAL_GPIO_Init(GPIOE, &GPIO_InitStruct);

  /*Configure GPIO pins : CS_I2C_SPI_Pin LD4_Pin LD3_Pin LD5_Pin
                           LD7_Pin LD9_Pin LD10_Pin LD8_Pin
                           LD6_Pin */
  GPIO_InitStruct.Pin = CS_I2C_SPI_Pin|LD4_Pin|LD3_Pin|LD5_Pin
                          |LD7_Pin|LD9_Pin|LD10_Pin|LD8_Pin
                          |LD6_Pin;
  GPIO_InitStruct.Mode = GPIO_MODE_OUTPUT_PP;
  GPIO_InitStruct.Pull = GPIO_NOPULL;
  GPIO_InitStruct.Speed = GPIO_SPEED_FREQ_LOW;
  HAL_GPIO_Init(GPIOE, &GPIO_InitStruct);

  /*Configure GPIO pins : B1_Pin PA15 */
  GPIO_InitStruct.Pin = B1_Pin|GPIO_PIN_15;
  GPIO_InitStruct.Mode = GPIO_MODE_INPUT;
  GPIO_InitStruct.Pull = GPIO_NOPULL;
  HAL_GPIO_Init(GPIOA, &GPIO_InitStruct);

  /*Configure GPIO pins : SPI1_SCK_Pin SPI1_MISO_Pin SPI1_MISOA7_Pin */
  GPIO_InitStruct.Pin = SPI1_SCK_Pin|SPI1_MISO_Pin|SPI1_MISOA7_Pin;
  GPIO_InitStruct.Mode = GPIO_MODE_AF_PP;
  GPIO_InitStruct.Pull = GPIO_NOPULL;
  GPIO_InitStruct.Speed = GPIO_SPEED_FREQ_LOW;
  GPIO_InitStruct.Alternate = GPIO_AF5_SPI1;
  HAL_GPIO_Init(GPIOA, &GPIO_InitStruct);

  /*Configure GPIO pin : PB0 */
  GPIO_InitStruct.Pin = GPIO_PIN_0;
  GPIO_InitStruct.Mode = GPIO_MODE_OUTPUT_PP;
  GPIO_InitStruct.Pull = GPIO_NOPULL;
  GPIO_InitStruct.Speed = GPIO_SPEED_FREQ_LOW;
  HAL_GPIO_Init(GPIOB, &GPIO_InitStruct);

  /*Configure GPIO pins : PB3 PB4 PB5 */
  GPIO_InitStruct.Pin = GPIO_PIN_3|GPIO_PIN_4|GPIO_PIN_5;
  GPIO_InitStruct.Mode = GPIO_MODE_IT_RISING;
  GPIO_InitStruct.Pull = GPIO_NOPULL;
  HAL_GPIO_Init(GPIOB, &GPIO_InitStruct);

  /*Configure GPIO pin : PB8 */
  GPIO_InitStruct.Pin = GPIO_PIN_8;
  GPIO_InitStruct.Mode = GPIO_MODE_INPUT;
  GPIO_InitStruct.Pull = GPIO_NOPULL;
  HAL_GPIO_Init(GPIOB, &GPIO_InitStruct);

  /* EXTI interrupt init*/
  HAL_NVIC_SetPriority(EXTI3_IRQn, 0, 0);
  HAL_NVIC_EnableIRQ(EXTI3_IRQn);

  HAL_NVIC_SetPriority(EXTI4_IRQn, 0, 0);
  HAL_NVIC_EnableIRQ(EXTI4_IRQn);

  HAL_NVIC_SetPriority(EXTI9_5_IRQn, 0, 0);
  HAL_NVIC_EnableIRQ(EXTI9_5_IRQn);

}

void _Error_Handler(char * file, int line)
{
  while(1)
  {
  }
}

/************************ (C) COPYRIGHT STMicroelectronics *****END OF FILE****/
